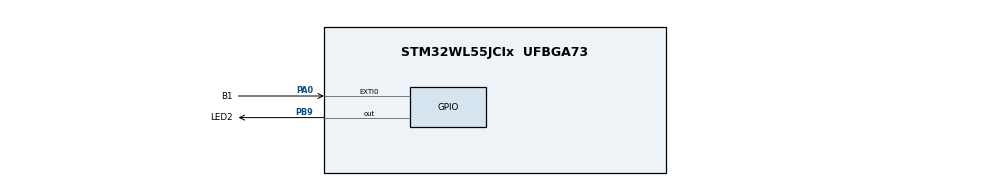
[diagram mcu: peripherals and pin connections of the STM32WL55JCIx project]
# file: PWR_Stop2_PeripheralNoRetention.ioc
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Mcu.Family=STM32WL
Mcu.Name=STM32WL55JCIx
Mcu.Package=UFBGA73
NVIC.EXTI0_IRQn=true\:0\:0\:false\:false\:true\:true\:true
NVIC.PriorityGroup=NVIC_PRIORITYGROUP_4
PA0.GPIO_Label=B1
PA0.GPIO_PuPd=GPIO_PULLUP
PA0.Signal=GPXTI0
PB9.GPIO_Label=LED2
PB9.Signal=GPIO_Output
ProjectManager.HeapSize=0x200
ProjectManager.StackSize=0x400
ProjectManager.TargetToolchain=EWARM V8
RCC.AHBFreq_Value=48000000
RCC.APB1Freq_Value=48000000
RCC.APB1TimFreq_Value=48000000
RCC.APB2Freq_Value=48000000
RCC.APB2TimFreq_Value=48000000
RCC.APB3Freq_Value=48000000
RCC.CortexFreq_Value=48000000
RCC.HCLKFreq_Value=48000000
RCC.HSE_VALUE=8000000
RCC.HSI_VALUE=16000000
RCC.LSE_VALUE=32768
RCC.MSIClockRange=RCC_MSIRANGE_11
RCC.RNGCLockSelection=RCC_RNGCLKSOURCE_MSI
RCC.SYSCLKFreq_VALUE=48000000
RCC.VCOOutputFreq_Value=384000000
VP_RNG_VS_RNG.Mode=RNG_Activate
board=custom

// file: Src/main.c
/* USER CODE BEGIN Header */
/**
  ******************************************************************************
  * @file    PWR/PWR_Stop2_PeripheralNoRetention/Src/main.c
  * @author  MCD Application Team
  * @brief   This example describes how to use low-power mode Stop2
  *          and peripherals not featuring retention of configuration.
  ******************************************************************************
  * @attention
  *
  * <h2><center>&copy; Copyright (c) 2020 STMicroelectronics.
  * All rights reserved.</center></h2>
  *
  * This software component is licensed by ST under BSD 3-Clause license,
  * the "License"; You may not use this file except in compliance with the
  * License. You may obtain a copy of the License at:
  *                        opensource.org/licenses/BSD-3-Clause
  *
  ******************************************************************************
  */
/* USER CODE END Header */
#include "main.h"

RNG_HandleTypeDef hrng;

/* USER CODE BEGIN PV */
__IO uint8_t ubUserButtonEvent = 0;   /* Flag of user button set on interrupt handler */
uint32_t Random32bit = 0;
/* USER CODE END PV */

void SystemClock_Config(void);
static void MX_GPIO_Init(void);
static void MX_RNG_Init(void);

int main(void)
{
  /* USER CODE BEGIN 1 */
  /* STM32WLxx HAL library initialization:
       - Configure the Flash prefetch
       - Systick timer is configured by default as source of time base, but user
         can eventually implement his proper time base source (a general purpose
         timer for example or other time source), keeping in mind that Time base
         duration should be kept 1ms since PPP_TIMEOUT_VALUEs are defined and
         handled in milliseconds basis.
       - Set NVIC Group Priority to 4
       - Low Level Initialization
     */
  /* USER CODE END 1 */

  /* MCU Configuration--------------------------------------------------------*/

  /* Reset of all peripherals, Initializes the Flash interface and the Systick. */
  HAL_Init();

  /* USER CODE BEGIN Init */

  /* Note: LED and user push-button are controlled by HAL BSP
           and initialized by CubeMX function MX_GPIO_Init.
  */

  /* USER CODE END Init */

  /* Configure the system clock */
  SystemClock_Config();

  /* Initialize all configured peripherals */
  MX_GPIO_Init();
  MX_RNG_Init();

  /* Infinite loop */
  while (1)
  {

    /* USER CODE BEGIN 3 */

    /* Generate random number */
    if (HAL_RNG_GenerateRandomNumber(&hrng, &Random32bit) != HAL_OK)
    {
      /* Random number generation error */
      Error_Handler();
    }

    if (HAL_RNG_GenerateRandomNumber(&hrng, &Random32bit) != HAL_OK)
    {
      /* Random number generation error */
      Error_Handler();
    }

    /* Wait for press on user button */
    ubUserButtonEvent = 0;
    while (ubUserButtonEvent == 0)
    {
      BSP_LED_Toggle(LED2);
      HAL_Delay(100);
    }

    /* Turn off LED before entering in low power mode */
    BSP_LED_Off(LED2);

    /* Debounce delay of user button */
    HAL_Delay(500);

    /* Request to enter in Stop2 mode */
    HAL_PWREx_EnterSTOP2Mode(PWR_STOPENTRY_WFI);

    /* Turn on LED during 1 sec */
    BSP_LED_On(LED2);
    HAL_Delay(1000);

    /* Re-initialize peripherals not featuring retention in system Stop2 mode */
    MX_RNG_Init();
  }
  /* USER CODE END 3 */
}

void SystemClock_Config(void)
{
  RCC_OscInitTypeDef RCC_OscInitStruct = {0};
  RCC_ClkInitTypeDef RCC_ClkInitStruct = {0};

  /** Configure the main internal regulator output voltage
  */
  __HAL_PWR_VOLTAGESCALING_CONFIG(PWR_REGULATOR_VOLTAGE_SCALE1);
  /** Initializes the CPU, AHB and APB busses clocks
  */
  RCC_OscInitStruct.OscillatorType = RCC_OSCILLATORTYPE_MSI;
  RCC_OscInitStruct.MSIState = RCC_MSI_ON;
  RCC_OscInitStruct.MSICalibrationValue = RCC_MSICALIBRATION_DEFAULT;
  RCC_OscInitStruct.MSIClockRange = RCC_MSIRANGE_11;
  RCC_OscInitStruct.PLL.PLLState = RCC_PLL_NONE;
  if (HAL_RCC_OscConfig(&RCC_OscInitStruct) != HAL_OK)
  {
    Error_Handler();
  }
  /** Configure the SYSCLKSource, HCLK, PCLK1 and PCLK2 clocks dividers
  */
  RCC_ClkInitStruct.ClockType = RCC_CLOCKTYPE_HCLK3|RCC_CLOCKTYPE_HCLK
                              |RCC_CLOCKTYPE_SYSCLK|RCC_CLOCKTYPE_PCLK1
                              |RCC_CLOCKTYPE_PCLK2;
  RCC_ClkInitStruct.SYSCLKSource = RCC_SYSCLKSOURCE_MSI;
  RCC_ClkInitStruct.AHBCLKDivider = RCC_SYSCLK_DIV1;
  RCC_ClkInitStruct.APB1CLKDivider = RCC_HCLK_DIV1;
  RCC_ClkInitStruct.APB2CLKDivider = RCC_HCLK_DIV1;
  RCC_ClkInitStruct.AHBCLK3Divider = RCC_SYSCLK_DIV1;

  if (HAL_RCC_ClockConfig(&RCC_ClkInitStruct, FLASH_LATENCY_2) != HAL_OK)
  {
    Error_Handler();
  }
}

static void MX_RNG_Init(void)
{

  hrng.Instance = RNG;
  hrng.Init.ClockErrorDetection = RNG_CED_ENABLE;
  if (HAL_RNG_Init(&hrng) != HAL_OK)
  {
    Error_Handler();
  }

}

static void MX_GPIO_Init(void)
{
  GPIO_InitTypeDef GPIO_InitStruct = {0};

  /* GPIO Ports Clock Enable */
  __HAL_RCC_GPIOB_CLK_ENABLE();
  __HAL_RCC_GPIOA_CLK_ENABLE();

  /*Configure GPIO pin Output Level */
  HAL_GPIO_WritePin(LED2_GPIO_Port, LED2_Pin, GPIO_PIN_RESET);

  /*Configure GPIO pin : LED2_Pin */
  GPIO_InitStruct.Pin = LED2_Pin;
  GPIO_InitStruct.Mode = GPIO_MODE_OUTPUT_PP;
  GPIO_InitStruct.Pull = GPIO_NOPULL;
  GPIO_InitStruct.Speed = GPIO_SPEED_FREQ_LOW;
  HAL_GPIO_Init(LED2_GPIO_Port, &GPIO_InitStruct);

  /*Configure GPIO pin : B1_Pin */
  GPIO_InitStruct.Pin = B1_Pin;
  GPIO_InitStruct.Mode = GPIO_MODE_IT_RISING;
  GPIO_InitStruct.Pull = GPIO_PULLUP;
  HAL_GPIO_Init(B1_GPIO_Port, &GPIO_InitStruct);

  /* EXTI interrupt init*/
  HAL_NVIC_SetPriority(EXTI0_IRQn, 0, 0);
  HAL_NVIC_EnableIRQ(EXTI0_IRQn);

}

/* USER CODE BEGIN 4 */

/**
  * @brief EXTI line detection callbacks
  * @param GPIO_Pin: Specifies the pins connected EXTI line
  * @retval None
  */
void HAL_GPIO_EXTI_Callback(uint16_t GPIO_Pin)
{
 if (GPIO_Pin == BUTTON_SW1_PIN)
 {
   /* Set variable to report push button event to main program */
   ubUserButtonEvent = 1;
 }
}
/* USER CODE END 4 */

void Error_Handler(void)
{
  /* USER CODE BEGIN Error_Handler_Debug */
  /* User can add his own implementation to report the HAL error return state */
  while(1)
  {
    HAL_GPIO_WritePin(LED2_GPIO_PORT, LED2_PIN, GPIO_PIN_SET);
  }
  /* USER CODE END Error_Handler_Debug */
}

/************************ (C) COPYRIGHT STMicroelectronics *****END OF FILE****/
